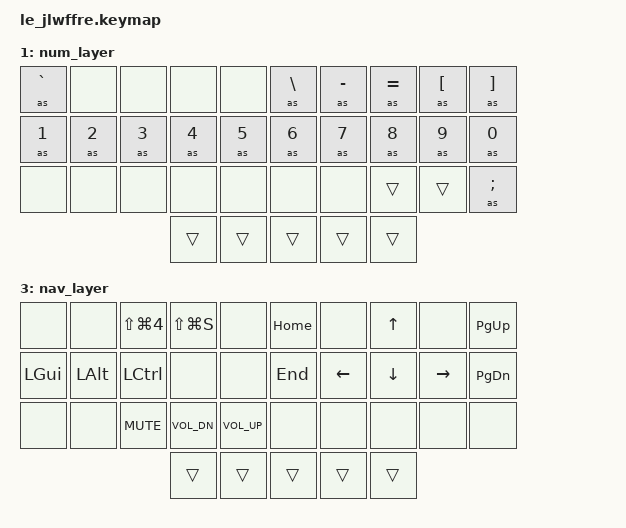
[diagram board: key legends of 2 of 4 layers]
/*
 * Copyright (c) 2022 The ZMK Contributors
 *
 * SPDX-License-Identifier: MIT
 */

#include <behaviors.dtsi>
#include <dt-bindings/zmk/keys.h>
#include <dt-bindings/zmk/bt.h>

// Home row mods macro
#define HRML(k1,k2,k3,k4) &ht LALT  k1 &ht LGUI   k2  &ht LCTRL k3 &ht LSHFT k4
#define HRMR(k1,k2,k3,k4) &ht RCTRL k1 &ht RSHFT k2  &ht RGUI  k3 &ht RALT   k4

/ {
    behaviors {
        ht: hold_tap {
            compatible = "zmk,behavior-hold-tap";
            #binding-cells = <2>;
            flavor = "balanced";
            tapping-term-ms = <200>;
            quick-tap-ms = <220>;
            require-prior-idle-ms = <125>;
            bindings = <&kp>, <&kp>;
        };
        mt: mod_tap {
            #binding-cells = <2>;
            tapping-term-ms = <200>;
            quick-tap-ms = <220>;
            require-prior-idle-ms = <125>;
            bindings = <&kp>, <&kp>;
        };
        as_ht: autoshift_hold_tap {
            compatible = "zmk,behavior-hold-tap";
            #binding-cells = <2>;
            tapping-term-ms = <200>;
            bindings = <&shifted>, <&kp>;
            flavor = "tap-preferred";
        };

        combos {
            compatible = "zmk,combos";
            combo_esc {
                timeout-ms = <50>;
                key-positions = <0 1>;
                bindings = <&kp ESC>;
            };
            combo_del {
                timeout-ms = <50>;
                key-positions = <8 9>;
                bindings = <&kp DEL>;
            };
            combo_reset {
                timeout-ms = <50>;
                key-positions = <0 9>;
                layers = <2>;
                bindings = <&sys_reset>;
            };
            combo_boot {
                timeout-ms = <50>;
                key-positions = <5 20>;
                layers = <2>;
                bindings = <&bootloader>;
            };
        };
    };

    macros {
        shifted: macro_shifted_kp {
            #binding-cells = <1>;
            compatible = "zmk,behavior-macro-one-param";
            bindings =
              <&macro_press &kp LSHFT>,
              <&macro_param_1to1 &macro_tap &kp MACRO_PLACEHOLDER>,
              <&macro_release &kp LSHFT>;
        };
        as: autoshift {
            compatible = "zmk,behavior-macro-one-param";
            #binding-cells = <1>;
            bindings =
              <&macro_press>,
              <&macro_param_1to1>,
              <&macro_param_1to2>,
              <&as_ht MACRO_PLACEHOLDER MACRO_PLACEHOLDER>,
              <&macro_pause_for_release>,
              <&macro_release>,
              <&macro_param_1to1>,
              <&macro_param_1to2>,
              <&as_ht MACRO_PLACEHOLDER MACRO_PLACEHOLDER>;
        };
    };

    keymap {
        compatible = "zmk,keymap";
        default_layer {
            bindings = <
        //╭──────────┬──────────┬──────────┬──────────┬──────────╮                      ╭──────────┬──────────┬──────────┬──────────┬──────────╮
        //│  Q       │  W       │  E       │  R       │  T       │                      │  Y       │  U       │  I       │  O       │  P       │
            &kp Q      &kp W      &kp E     &kp R       &kp T                             &kp Y      &kp U      &kp I      &kp O      &kp P
        //├──────────┼──────────┼──────────┼──────────┼──────────┤                      ├──────────┼──────────┼──────────┼──────────┼──────────┤
        //│  A       │  S       │  D       │  F       │  G       │                      │  H       │  J       │  K       │  L       │ ' "      │
            HRML(A,     S,         D,         F)        &kp G                             &kp H      HRMR(J,      K,         L,        SQT)
        //├──────────┼──────────┼──────────┼──────────┼──────────┤                      ├──────────┼──────────┼──────────┼──────────┼──────────┤
        //│  Z       │  X       │  C       │  V       │  B       │                      │  N       │  M       │ , <      │ . >      │ / ?      │
            &kp Z      &kp X      &kp C      &kp V      &kp B                             &kp N      &kp M      &kp COMMA  &kp DOT    &kp FSLH
        //╰──────────┴──────────┴──────────┼──────────┼──────────┤                      ├──────────┼──────────┼──────────┴──────────┴──────────╯
                                            &lt 3 TAB  &lt 1 SPACE   &kp C_MUTE   &mt 1 LSHIFT BSPC &lt 2 RET
        //                                 ╰──────────┴──────────╯                      ╰──────────┴──────────╯
            >;
            sensor-bindings = <&inc_dec_kp C_VOL_UP C_VOL_DN>;
        };

        num_layer {
            bindings = <
        //╭──────────┬──────────┬──────────┬──────────┬──────────╮      ╭──────────┬──────────┬──────────┬──────────┬──────────╮
        //│  ` ~     │          │          │          │          │      │  \ |     │  - _     │  = +     │  [       │  ]       │
            &as GRAVE  &none      &none      &none      &none             &as BSLH   &as MINUS  &as EQUAL  &as LBKT   &as RBKT
        //├──────────┼──────────┼──────────┼──────────┼──────────┤      ├──────────┼──────────┼──────────┼──────────┼──────────┤
        //│  1 !     │  2 @     │  3 #     │  4 $     │  5 %     │      │  6 ^     │  7 &     │  8 *     │  9 (     │  0 )     │
            &as N1     &as N2     &as N3     &as N4     &as N5            &as N6     &as N7     &as N8     &as N9     &as N0
        //├──────────┼──────────┼──────────┼──────────┼──────────┤      ├──────────┼──────────┼──────────┼──────────┼──────────┤
        //│          │          │          │          │          │      │          │          │          │          │          │
            &none      &none      &none      &none      &none             &none      &none      &trans     &trans     &as SEMI
        //╰──────────┴──────────┴──────────┼──────────┼──────────┤      ├──────────┼──────────┼──────────┴──────────┴──────────╯
                                             &trans     &trans    &trans  &trans     &trans
        //                                 ╰──────────┴──────────╯      ╰──────────┴──────────╯
            >;
            sensor-bindings = <&inc_dec_kp C_VOL_UP C_VOL_DN>;
        };

        fn_layer {
            bindings = <
        //╭──────────┬──────────┬──────────┬──────────┬──────────╮      ╭──────────┬──────────┬──────────┬──────────┬──────────╮
        //│          │          │          │          │          │      │          │          │          │  F11     │  F12     │
            &bt BT_CLR  &bt BT_SEL 0 &bt BT_SEL 1 &bt BT_SEL 2 &none      &none      &none      &none      &kp F11    &kp F12
        //├──────────┼──────────┼──────────┼──────────┼──────────┤      ├──────────┼──────────┼──────────┼──────────┼──────────┤
        //│  F1      │  F2      │  F3      │  F4      │  F5      │      │  F6      │  F7      │  F8      │  F9      │  F10     │
            HRML(F1,    F2,        F3,        F4)       &kp F5            &kp F6     HRMR(F7,    F8,        F9,        F10)
        //├──────────┼──────────┼──────────┼──────────┼──────────┤      ├──────────┼──────────┼──────────┼──────────┼──────────┤
        //│          │          │          │          │          │      │          │          │          │          │          │
            &none      &none      &none      &none      &none             &none      &none      &none      &none      &none
        //╰──────────┴──────────┴──────────┼──────────┼──────────┤      ├──────────┼──────────┼──────────┴──────────┴──────────╯
                                             &trans     &trans    &trans  &trans     &trans
        //                                 ╰──────────┴──────────╯      ╰──────────┴──────────╯
            >;
            sensor-bindings = <&inc_dec_kp C_VOL_UP C_VOL_DN>;
        };

        nav_layer {
            bindings = <
        //╭──────────┬──────────┬──────────┬──────────┬──────────╮      ╭──────────┬──────────┬──────────┬──────────┬──────────╮
        //│          │          │          │          │          │      │  HOME    │          │  UP      │          │  PG_UP   │
            &none      &none  &kp LS(LG(N4)) &kp LS(LG(S)) &none         &kp HOME   &none      &kp UP     &none      &kp PG_UP
        //├──────────┼──────────┼──────────┼──────────┼──────────┤      ├──────────┼──────────┼──────────┼──────────┼──────────┤
        //│  LGUI    │  LALT    │  LCTRL   │          │          │      │  END     │  LEFT    │  DOWN    │  RIGHT   │  PG_DN   │
            &kp LGUI   &kp LALT   &kp LCTRL  &none      &none             &kp END    &kp LEFT   &kp DOWN  &kp RIGHT  &kp PG_DN
        //├──────────┼──────────┼──────────┼──────────┼──────────┤      ├──────────┼──────────┼──────────┼──────────┼──────────┤
        //│          │          │          │          │          │      │          │          │          │          │          │
            &none      &none      &kp C_MUTE &kp C_VOL_DN &kp C_VOL_UP    &none      &none      &none      &none      &none
        //╰──────────┴──────────┴──────────┼──────────┼──────────┤      ├──────────┼──────────┼──────────┴──────────┴──────────╯
                                             &trans     &trans    &trans  &trans     &trans
        //                                 ╰──────────┴──────────╯      ╰──────────┴──────────╯
            >;
            sensor-bindings = <&inc_dec_kp C_VOL_UP C_VOL_DN>;
        };

    };

};
